AUTOSAR XML (schema 00050)
package /ComponentTypes
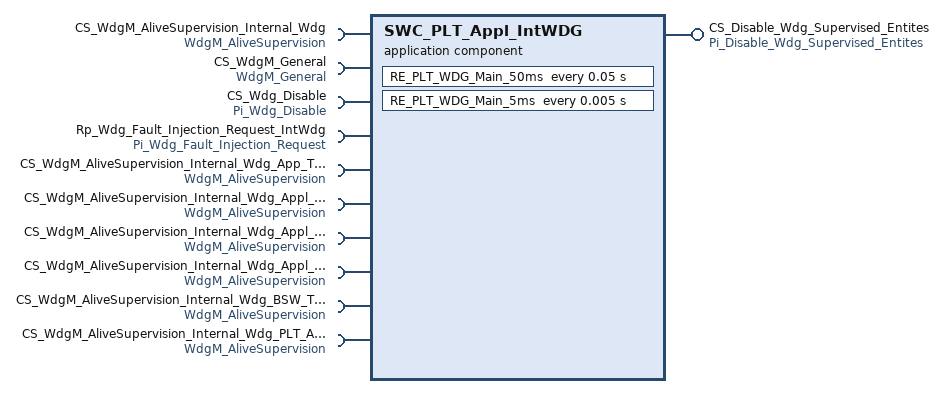
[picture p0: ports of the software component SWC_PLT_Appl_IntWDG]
  application sw component type SWC_PLT_Appl_IntWDG
    10 x require port:
      CS_WdgM_AliveSupervision_Internal_Wdg: client-com-spec=CheckpointReached, required-interface=WdgM_AliveSupervision
      CS_WdgM_General: required-interface=WdgM_General
        required-com-specs:
          GetFirstExpiredSEID
          GetGlobalStatus
          GetLocalStatus
          GetMode
          PerformReset
          SetMode
          ActivateSupervisionEntity
          DeactivateSupervisionEntity
      CS_Wdg_Disable: client-com-spec=Read, required-interface=Pi_Wdg_Disable
      Rp_Wdg_Fault_Injection_Request_IntWdg: nonqueued-receiver-com-spec{data-element=De_Wdg_Fault_Injection_Request, filter=data-filter-type=ALWAYS, init-value=0}, required-interface=Pi_Wdg_Fault_Injection_Request
      CS_WdgM_AliveSupervision_Internal_Wdg_App_Task_General_1: client-com-spec=CheckpointReached, required-interface=WdgM_AliveSupervision
      CS_WdgM_AliveSupervision_Internal_Wdg_Appl_IPC_Task: client-com-spec=CheckpointReached, required-interface=WdgM_AliveSupervision
      CS_WdgM_AliveSupervision_Internal_Wdg_Appl_Task_Communication: client-com-spec=CheckpointReached, required-interface=WdgM_AliveSupervision
      CS_WdgM_AliveSupervision_Internal_Wdg_Appl_Task_Radar_Control: client-com-spec=CheckpointReached, required-interface=WdgM_AliveSupervision
      CS_WdgM_AliveSupervision_Internal_Wdg_BSW_Task: client-com-spec=CheckpointReached, required-interface=WdgM_AliveSupervision
      CS_WdgM_AliveSupervision_Internal_Wdg_PLT_Appl_Task: client-com-spec=CheckpointReached, required-interface=WdgM_AliveSupervision
    provide port CS_Disable_Wdg_Supervised_Entites: server-com-spec{operation=Operation, queue-length=1}, provided-interface=Pi_Disable_Wdg_Supervised_Entites
    behavior SWC_PLT_Appl_IntWDG_InternalBehavior: handle-termination-and-restart=NO-SUPPORT
      init event SWC_PLT_Appl_Wdg_InitEvent: start-on-event=RE_PLT_Wdg_Init
      timing event TMT_RE_PLT_WDG_Main_50ms: start-on-event=RE_PLT_WDG_Main_50ms, period=0.05
      timing event TMT_RE_PLT_WDG_Main_5ms: start-on-event=RE_PLT_WDG_Main_5ms, period=0.005
      operation invoked event OIT_CS_Disable_Wdg_Supervised_Entites_Operation_CS_Disable_Wdg_Supervised_Entites_Operation: start-on-event=CS_Disable_Wdg_Supervised_Entites_Operation, operation=CS_Disable_Wdg_Supervised_Entites.Operation
      5 x timing event:
        TMT_RE_PLT_WDG_INTERNAL_WDG_Appl_IPC_Task: start-on-event=RE_PLT_WDG_INTERNAL_WDG_Appl_IPC_Task, period=0.05
        TMT_RE_PLT_WDG_INTERNAL_WDG_Appl_Task_Communication: start-on-event=RE_PLT_WDG_INTERNAL_WDG_Appl_Task_Communication, period=0.025
        TMT_RE_PLT_WDG_INTERNAL_WDG_Appl_Task_Radar_Control: start-on-event=RE_PLT_WDG_INTERNAL_WDG_Appl_Task_Radar_Control, period=0.05
        TMT_RE_PLT_WDG_INTERNAL_WDG_BSW_Task: start-on-event=RE_PLT_WDG_INTERNAL_WDG_BSW_Task, period=0.025
        TMT_RE_PLT_WDG_INTERNAL_WDG_PLT_Appl_Task: start-on-event=RE_PLT_WDG_INTERNAL_WDG_PLT_Appl_Task, period=0.025
      9 x runnable:
        RE_PLT_Wdg_Init
          8 x sync call:
            SC_CS_WdgM_General_ActivateSupervisionEntity: operation=CS_WdgM_General.ActivateSupervisionEntity
            SC_CS_WdgM_General_DeactivateSupervisionEntity: operation=CS_WdgM_General.DeactivateSupervisionEntity
            SC_CS_WdgM_General_GetFirstExpiredSEID: operation=CS_WdgM_General.GetFirstExpiredSEID
            SC_CS_WdgM_General_GetGlobalStatus: operation=CS_WdgM_General.GetGlobalStatus
            SC_CS_WdgM_General_GetLocalStatus: operation=CS_WdgM_General.GetLocalStatus
            SC_CS_WdgM_General_GetMode: operation=CS_WdgM_General.GetMode
            SC_CS_WdgM_General_PerformReset: operation=CS_WdgM_General.PerformReset
            SC_CS_WdgM_General_SetMode: operation=CS_WdgM_General.SetMode
        RE_PLT_WDG_Main_50ms: minimum-start-interval=0.05
          data-receive-point-by-arguments:
            access REC_Rp_Wdg_Fault_Injection_Request_IntWdg_De_Wdg_Fault_Injection_Request: accessed-variable=Rp_Wdg_Fault_Injection_Request_IntWdg.De_Wdg_Fault_Injection_Request
        RE_PLT_WDG_Main_5ms: minimum-start-interval=0.005
          10 x sync call:
            SC_CS_WdgM_AliveSupervision_Internal_Wdg_CheckpointReached: operation=CS_WdgM_AliveSupervision_Internal_Wdg.CheckpointReached
            SC_CS_WdgM_General_ActivateSupervisionEntity: operation=CS_WdgM_General.ActivateSupervisionEntity
            SC_CS_WdgM_General_DeactivateSupervisionEntity: operation=CS_WdgM_General.DeactivateSupervisionEntity
            SC_CS_WdgM_General_GetFirstExpiredSEID: operation=CS_WdgM_General.GetFirstExpiredSEID
            SC_CS_WdgM_General_GetGlobalStatus: operation=CS_WdgM_General.GetGlobalStatus
            SC_CS_WdgM_General_GetLocalStatus: operation=CS_WdgM_General.GetLocalStatus
            SC_CS_WdgM_General_GetMode: operation=CS_WdgM_General.GetMode
            SC_CS_WdgM_General_PerformReset: operation=CS_WdgM_General.PerformReset
            SC_CS_WdgM_General_SetMode: operation=CS_WdgM_General.SetMode
            SC_Pi_Wdg_Disable: operation=CS_Wdg_Disable.Read
        CS_Disable_Wdg_Supervised_Entites_Operation
        RE_PLT_WDG_INTERNAL_WDG_Appl_IPC_Task
          sync call SC_CS_WdgM_AliveSupervision_Internal_Wdg_Appl_IPC_Task_CheckpointReached: operation=CS_WdgM_AliveSupervision_Internal_Wdg_Appl_IPC_Task.CheckpointReached
        RE_PLT_WDG_INTERNAL_WDG_Appl_Task_Communication
          sync call SC_CS_WdgM_AliveSupervision_Internal_Wdg_Appl_Task_Communication_CheckpointReached: operation=CS_WdgM_AliveSupervision_Internal_Wdg_Appl_Task_Communication.CheckpointReached
        RE_PLT_WDG_INTERNAL_WDG_Appl_Task_Radar_Control
          sync call SC_CS_WdgM_AliveSupervision_Internal_Wdg_Appl_Task_Radar_Control_CheckpointReached: operation=CS_WdgM_AliveSupervision_Internal_Wdg_Appl_Task_Radar_Control.CheckpointReached
        RE_PLT_WDG_INTERNAL_WDG_BSW_Task
          sync call SC_CS_WdgM_AliveSupervision_Internal_Wdg_BSW_Task_CheckpointReached: operation=CS_WdgM_AliveSupervision_Internal_Wdg_BSW_Task.CheckpointReached
        RE_PLT_WDG_INTERNAL_WDG_PLT_Appl_Task
          sync call SC_CS_WdgM_AliveSupervision_Internal_Wdg_PLT_Appl_Task_CheckpointReached: operation=CS_WdgM_AliveSupervision_Internal_Wdg_PLT_Appl_Task.CheckpointReached
  swc implementation SWC_PLT_Appl_IntWDG_Implementation: behavior=SWC_PLT_Appl_IntWDG_InternalBehavior
    code-descriptors:
      code Default: artifact-descriptors=autosar-engineering-object=category=SWSRC
